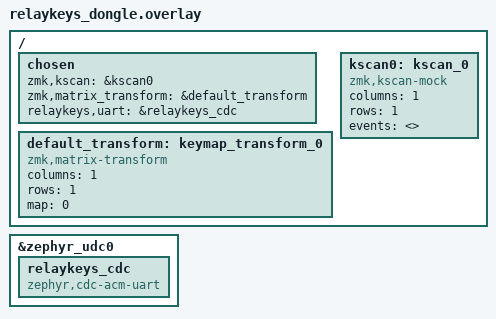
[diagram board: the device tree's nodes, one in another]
/ {
    chosen {
        zmk,kscan = &kscan0;
        zmk,matrix_transform = &default_transform;
        relaykeys,uart = &relaykeys_cdc;
    };

    default_transform: keymap_transform_0 {
        compatible = "zmk,matrix-transform";
        columns = <1>;
        rows = <1>;
        map = <0>;
    };

    kscan0: kscan_0 {
        compatible = "zmk,kscan-mock";
        columns = <1>;
        rows = <1>;
        events = <>;
    };
};

&zephyr_udc0 {
    relaykeys_cdc: relaykeys_cdc {
        compatible = "zephyr,cdc-acm-uart";
    };
};
